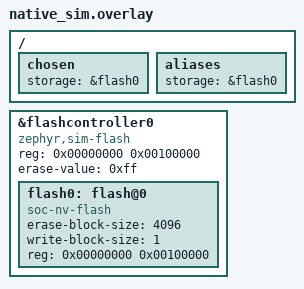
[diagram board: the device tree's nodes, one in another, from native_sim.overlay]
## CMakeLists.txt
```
cmake_minimum_required(VERSION 3.20.0)

set(FSW_ROOT ${CMAKE_CURRENT_SOURCE_DIR}/../../..)

find_package(Zephyr REQUIRED HINTS $ENV{ZEPHYR_BASE})
project(raw_datalogger LANGUAGES CXX)

target_compile_options(app PRIVATE -Wall -Wextra -Wno-unused-parameter -Wno-unused-function -Wno-ignored-qualifiers)
FILE(GLOB app_sources src/*.cpp)
target_sources(app PRIVATE ${app_sources})
```

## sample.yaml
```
sample:
  description:
  name: raw_datalogger
common:
  build_only: true
  platform_allow:
    - native_sim
    - nucleo_f446re
tests:
  samples.template.default: {}
```

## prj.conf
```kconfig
CONFIG_CPP=y
CONFIG_REQUIRES_FULL_LIBCPP=y
CONFIG_STD_CPP20=y

CONFIG_F_CORE=y
CONFIG_F_CORE_OS=y

 # outputs
CONFIG_SERIAL=y
CONFIG_HEAP_MEM_POOL_SIZE=8192

CONFIG_DEBUG=y
CONFIG_CBPRINTF_FP_SUPPORT=y

CONFIG_MAIN_STACK_SIZE=8192
CONFIG_FLASH=y
CONFIG_SHELL=y
CONFIG_FLASH_SHELL=y
CONFIG_FLASH_MAP=y
CONFIG_FLASH_PAGE_LAYOUT=y
CONFIG_FLASH_SIMULATOR=y
CONFIG_STREAM_FLASH=y

CONFIG_LOG=y
```

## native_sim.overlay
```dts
	/ {
	chosen {
		storage = &flash0;
	};

	aliases {
		storage = &flash0;
	};
};

&flashcontroller0 {
    status = "okay";
    compatible = "zephyr,sim-flash";
    reg = <0x00000000 0x00100000>;

    #address-cells = <1>;
    #size-cells = <1>;
    erase-value = <0xff>;

    flash0: flash@0 {
        status = "okay";
        compatible = "soc-nv-flash";
        erase-block-size = <4096>;
        write-block-size = <1>;
        reg = <0x00000000 0x00100000>;
    };
};
```

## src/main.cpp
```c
#include "zephyr/logging/log.h"

#include <f_core/os/c_raw_datalogger.h>
#include <zephyr/kernel.h>

LOG_MODULE_REGISTER(main);

struct TestData {
    const char name[16];
    int a;
    int b;
    int c;
    int d;
};

int main() {
    const device* flash = DEVICE_DT_GET(DT_CHOSEN(zephyr_flash_controller));
    if (!device_is_ready(flash)) {
        LOG_ERR("Flash device not ready!");
        return -1;
    } else {
        // Print flash size
        uint64_t flashSize = 0;
        int ret = flash_get_size(flash, &flashSize);
        if (ret < 0) {
            LOG_ERR("Failed to get flash size: %d", ret);
            return -1;
        }

        LOG_INF("Flash Size: %llu bytes", flashSize);
    }
    off_t start_addr = 0x00000000;
    size_t erase_size = 0x00100000; // 1 MiB

    int err = flash_erase(flash, start_addr, erase_size);
    if (err < 0) {
        LOG_ERR("Failed to erase flash: %d", err);
        return -1;
    }

    // Fixed
    off_t nextAddr = 0x00000000;
    const int packetsInFixedFile = 5;
    const size_t fixedFileSize = sizeof(TestData) * packetsInFixedFile + sizeof(DataloggerMetadata);
    CRawDataLogger<TestData, 3> fixedLogger(flash, nextAddr, fixedFileSize, "test_fixed", DataloggerMode::Fixed);
    for (int i = 0; i < packetsInFixedFile; ++i) {
        char iter = '0' + i;
        TestData data = { "fixed", iter, iter, iter, iter };
        int ret = fixedLogger.Write(data);
        if (ret < 0) {
            LOG_ERR("Error writing data for fixed: %d", ret);
        } else {
            LOG_INF("Successfully wrote %d entries to fixed logger", i + 1);
        }
    }
    LOG_INF("Finished writing data for fixed logger.");
    if (fixedLogger.Write(TestData{ "fixed_overflow", 'B', 'A', 'D', '!' }) != -ENOSPC) {
        LOG_ERR("Error: Should not have been able to write more data to fixed logger");
    }

    nextAddr += fixedFileSize;

    // LinkedFixed
    const size_t linkedFixedFileSize = (sizeof(TestData) * 5) + sizeof(DataloggerMetadata);
    CRawDataLogger<TestData, 3> linkedFixedLogger(flash, nextAddr, linkedFixedFileSize, "test_link_fixed", DataloggerMode::LinkedFixed);
    for (int i = 0; i < 5; ++i) {
        char iter = '0' + i;
        TestData data = { "linked_fixed", iter, iter, iter, iter };
        int ret = linkedFixedLogger.Write(data);
        if (ret < 0) {
            LOG_ERR("Error writing data for linked fixed: %d", ret);
        } else {
            LOG_INF("Successfully wrote %d entries to linked fix logger", i + 1);
        }
    }

    LOG_INF("Finished writing data for linked fixed logger.");


    nextAddr += linkedFixedFileSize;
    // Add a file in between to test finding next linked space using a fixed logger
    const size_t intermediateFileSize = sizeof(TestData) + sizeof(DataloggerMetadata);
    CRawDataLogger<TestData, 1> intermediateLogger(flash, nextAddr, intermediateFileSize, "intermediate", DataloggerMode::Fixed);
    TestData intermediateData = { "intermediate", 'I', 'N', 'T', 'R' };
    intermediateLogger.Write(intermediateData);
    if (intermediateLogger.GetLastError() != 0) {
        LOG_ERR("Error writing intermediate data: %d", intermediateLogger.GetLastError());
    }

    LOG_INF("Finished writing data for intermediate fixed logger");

    // LinkedFixed should skip the intermediate file and create 2 new files consecutively
    for (int i = 0; i < 10; ++i) {
        char iter = '0' + i;

        TestData data = { "linked_fixed2", iter, iter, iter, iter };
        int ret = linkedFixedLogger.Write(data);
        if (ret < 0) {
            LOG_ERR("Error writing data for linked fixed 2: %d", ret);
        } else {
            LOG_INF("Successfully wrote %d entries to linked fixed logger", i + 1);
        }
    }

    LOG_INF("Finished writing more data for linked fixed logger.");

    nextAddr += intermediateFileSize + (2 * linkedFixedFileSize); // Move past the intermediate and 2 linked fixed files

    // Test LinkedTruncate
    const size_t linkedTruncateFileSize = (sizeof(TestData) * 5) + sizeof(DataloggerMetadata);
    CRawDataLogger<TestData, 3> linkedTruncateLogger(flash, nextAddr, linkedTruncateFileSize, "test_link_trunc", DataloggerMode::LinkedTruncate);

    nextAddr += ((linkedTruncateFileSize * 2) + sizeof(DataloggerMetadata)) - (sizeof(TestData) * 2); // Leave space for 2 files minus 2 entries to test truncation
    CRawDataLogger<TestData, 1> anotherIntermediateLogger(flash, nextAddr, intermediateFileSize, "intermediate2", DataloggerMode::Fixed);
    anotherIntermediateLogger.Write(intermediateData);

    if (anotherIntermediateLogger.GetLastError() != 0) {
        LOG_ERR("Error writing another intermediate data: %d", anotherIntermediateLogger.GetLastError());
    }
    LOG_INF("Finished writing data for another intermediate fixed logger");


    for (int i = 0; i < 15; ++i) {
        char iter = '0' + (i % 10);

        TestData data = { "linked_truncate", iter, iter, iter, iter  };
        int ret = linkedTruncateLogger.Write(data);

        if (ret < 0) {
            LOG_ERR("Error writing data for linked truncate: %d", ret);
        } else {
            LOG_INF("Successfully wrote %d entries to linked truncate logger", i + 1);
        }
    }

    LOG_INF("Finished writing data for linked truncate logger");

    return 0;
}
```
